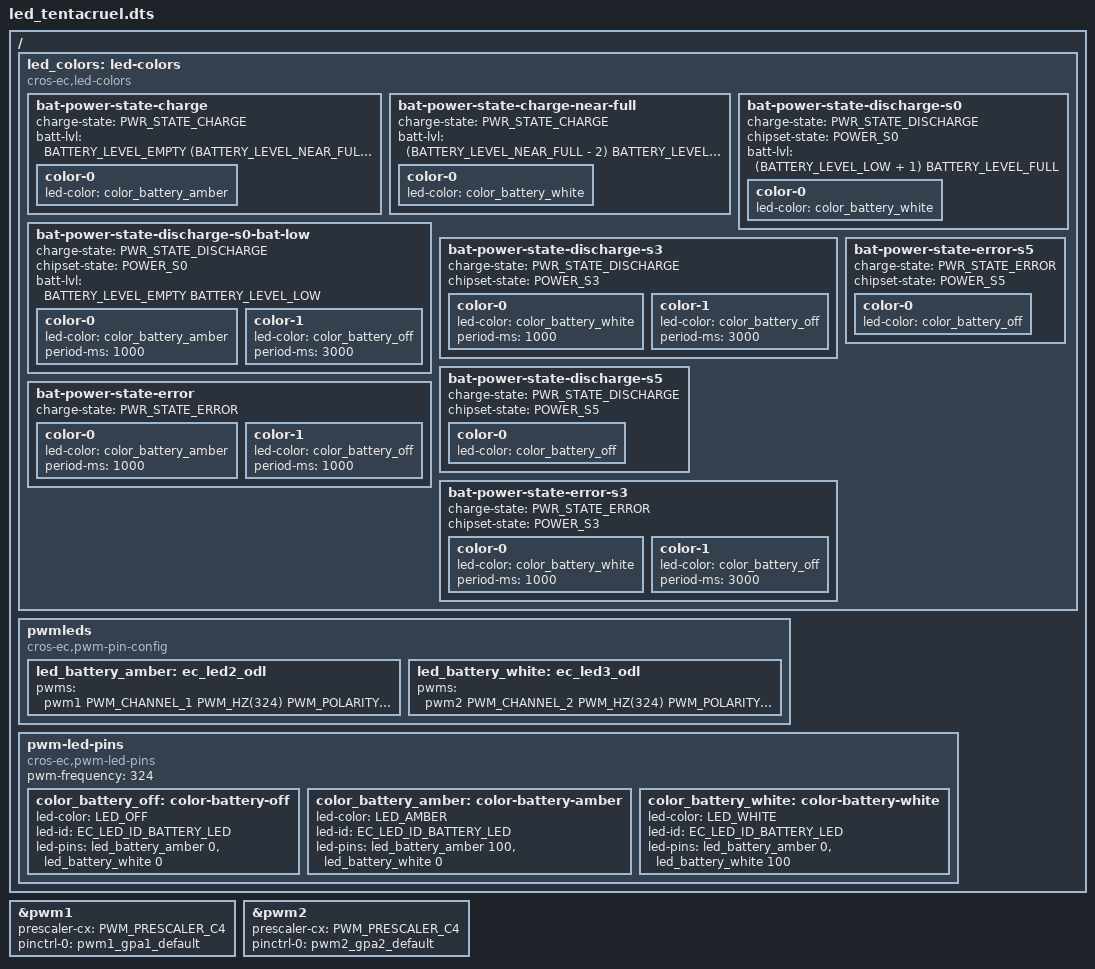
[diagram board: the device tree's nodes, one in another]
/* Copyright 2022 The ChromiumOS Authors.
 * Use of this source code is governed by a BSD-style license that can be
 * found in the LICENSE file.
 */
#include <dt-bindings/battery.h>

/ {
	led_colors: led-colors {
		compatible = "cros-ec,led-colors";

		/* Tentacruel LED bat charge */
		bat-power-state-charge {
			charge-state = "PWR_STATE_CHARGE";
			/* Battery percent range (>= Empty, <= 94%) */
			batt-lvl = <BATTERY_LEVEL_EMPTY
				   (BATTERY_LEVEL_NEAR_FULL - 3)>;
			color-0 {
				led-color = <&color_battery_amber>;
			};
		};

		bat-power-state-charge-near-full {
			charge-state = "PWR_STATE_CHARGE";
			/* Battery percent range (>= 95%, <= Full) */
			batt-lvl = <(BATTERY_LEVEL_NEAR_FULL - 2)
				     BATTERY_LEVEL_FULL>;
			color-0 {
				led-color = <&color_battery_white>;
			};
		};

		/* Tentacruel LED bat discharge */
		bat-power-state-discharge-s0 {
			charge-state = "PWR_STATE_DISCHARGE";
			chipset-state = "POWER_S0";
			/* Battery percent range (>= 11%, <= Full) */
			batt-lvl = <(BATTERY_LEVEL_LOW + 1) BATTERY_LEVEL_FULL>;

			color-0 {
				led-color = <&color_battery_white>;
			};
		};

		bat-power-state-discharge-s0-bat-low {
			charge-state = "PWR_STATE_DISCHARGE";
			chipset-state = "POWER_S0";
			/* Battery percent range (>= Empty, <= Low) */
			batt-lvl = <BATTERY_LEVEL_EMPTY BATTERY_LEVEL_LOW>;

			color-0 {
				led-color = <&color_battery_amber>;
				period-ms = <1000>;
			};

			color-1 {
				led-color = <&color_battery_off>;
				period-ms = <3000>;
			};
		};

		bat-power-state-discharge-s3 {
			charge-state = "PWR_STATE_DISCHARGE";
			chipset-state = "POWER_S3";

			color-0 {
				led-color = <&color_battery_white>;
				period-ms = <1000>;
			};

			color-1 {
				led-color = <&color_battery_off>;
				period-ms = <3000>;
			};
		};

		bat-power-state-discharge-s5 {
			charge-state = "PWR_STATE_DISCHARGE";
			chipset-state = "POWER_S5";
			color-0 {
				led-color = <&color_battery_off>;
			};
		};

		/* Tentacruel LED bat error */
		bat-power-state-error {
			charge-state = "PWR_STATE_ERROR";

			color-0 {
				led-color = <&color_battery_amber>;
				period-ms = <1000>;
			};

			color-1 {
				led-color = <&color_battery_off>;
				period-ms = <1000>;
			};
		};

		bat-power-state-error-s3 {
			charge-state = "PWR_STATE_ERROR";
			chipset-state = "POWER_S3";

			color-0 {
				led-color = <&color_battery_white>;
				period-ms = <1000>;
			};

			color-1 {
				led-color = <&color_battery_off>;
				period-ms = <3000>;
			};
		};

		bat-power-state-error-s5 {
			charge-state = "PWR_STATE_ERROR";
			chipset-state = "POWER_S5";

			color-0 {
				led-color = <&color_battery_off>;
			};
		};
	};

	pwmleds {
		compatible = "cros-ec,pwm-pin-config";

		led_battery_amber: ec_led2_odl {
			#led-pin-cells = <1>;
			pwms = <&pwm1
				PWM_CHANNEL_1
				PWM_HZ(324)
				PWM_POLARITY_INVERTED>;
		};
		led_battery_white: ec_led3_odl {
			#led-pin-cells = <1>;
			pwms = <&pwm2
				PWM_CHANNEL_2
				PWM_HZ(324)
				PWM_POLARITY_INVERTED>;
		};
	};

	pwm-led-pins {
		compatible = "cros-ec,pwm-led-pins";
		pwm-frequency = <324>;

		color_battery_off: color-battery-off {
			led-color = "LED_OFF";
			led-id = "EC_LED_ID_BATTERY_LED";
			led-pins = <&led_battery_amber 0>,
				   <&led_battery_white 0>;
		};

		color_battery_amber: color-battery-amber {
			led-color = "LED_AMBER";
			led-id = "EC_LED_ID_BATTERY_LED";
			led-pins = <&led_battery_amber 100>,
				   <&led_battery_white 0>;
		};

		color_battery_white: color-battery-white {
			led-color = "LED_WHITE";
			led-id = "EC_LED_ID_BATTERY_LED";
			led-pins = <&led_battery_amber 0>,
				   <&led_battery_white 100>;
		};
	};
};

/* LED1 */
&pwm1 {
	status = "okay";
	prescaler-cx = <PWM_PRESCALER_C4>;
	pinctrl-0 = <&pwm1_gpa1_default>;
	pinctrl-names = "default";
};

/* LED2 */
&pwm2 {
	status = "okay";
	prescaler-cx = <PWM_PRESCALER_C4>;
	pinctrl-0 = <&pwm2_gpa2_default>;
	pinctrl-names = "default";
};
